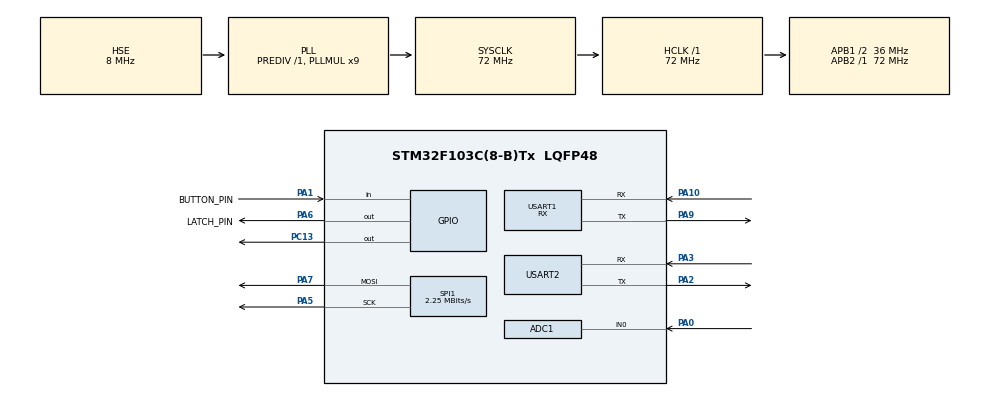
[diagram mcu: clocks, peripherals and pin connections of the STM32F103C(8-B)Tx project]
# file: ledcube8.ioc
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ADC1.Channel-2\#ChannelRegularConversion=ADC_CHANNEL_0
ADC1.NbrOfConversionFlag=1
ADC1.Rank-2\#ChannelRegularConversion=1
ADC1.SamplingTime-2\#ChannelRegularConversion=ADC_SAMPLETIME_1CYCLE_5
ADC1.master=1
Mcu.Family=STM32F1
Mcu.Name=STM32F103C(8-B)Tx
Mcu.Package=LQFP48
NVIC.PriorityGroup=NVIC_PRIORITYGROUP_4
NVIC.TIM2_IRQn=true\:2\:0\:true\:false\:true\:true\:true\:true
NVIC.USART1_IRQn=true\:0\:0\:false\:false\:true\:true\:true\:true
NVIC.USART2_IRQn=true\:0\:0\:false\:false\:true\:true\:true\:true
PA0-WKUP.Signal=ADCx_IN0
PA1.GPIO_Label=BUTTON_PIN
PA1.GPIO_PuPd=GPIO_PULLUP
PA1.Signal=GPIO_Input
PA10.Mode=Asynchronous
PA10.Signal=USART1_RX
PA13.Mode=Serial_Wire
PA13.Signal=SYS_JTMS-SWDIO
PA14.Mode=Serial_Wire
PA14.Signal=SYS_JTCK-SWCLK
PA2.Mode=Asynchronous
PA2.Signal=USART2_TX
PA3.Mode=Asynchronous
PA3.Signal=USART2_RX
PA5.Mode=TX_Only_Simplex_Unidirect_Master
PA5.Signal=SPI1_SCK
PA6.GPIO_Label=LATCH_PIN
PA6.Signal=GPIO_Output
PA7.Mode=TX_Only_Simplex_Unidirect_Master
PA7.Signal=SPI1_MOSI
PA9.Mode=Asynchronous
PA9.Signal=USART1_TX
PC13-TAMPER-RTC.Signal=GPIO_Output
PD0-OSC_IN.Mode=HSE-External-Oscillator
PD0-OSC_IN.Signal=RCC_OSC_IN
PD1-OSC_OUT.Mode=HSE-External-Oscillator
PD1-OSC_OUT.Signal=RCC_OSC_OUT
ProjectManager.HeapSize=0x200
ProjectManager.StackSize=0x400
ProjectManager.TargetToolchain=STM32CubeIDE
RCC.ADCPresc=RCC_ADCPCLK2_DIV6
RCC.AHBFreq_Value=72000000
RCC.APB1CLKDivider=RCC_HCLK_DIV2
RCC.APB1Freq_Value=36000000
RCC.APB1TimFreq_Value=72000000
RCC.APB2Freq_Value=72000000
RCC.APB2TimFreq_Value=72000000
RCC.HCLKFreq_Value=72000000
RCC.PLLMUL=RCC_PLL_MUL9
RCC.PLLSourceVirtual=RCC_PLLSOURCE_HSE
RCC.SYSCLKFreq_VALUE=72000000
RCC.SYSCLKSource=RCC_SYSCLKSOURCE_PLLCLK
RCC.USBFreq_Value=72000000
SH.ADCx_IN0.0=ADC1_IN0,IN0
SPI1.BaudRatePrescaler=SPI_BAUDRATEPRESCALER_32
SPI1.CalculateBaudRate=2.25 MBits/s
SPI1.Direction=SPI_DIRECTION_2LINES
SPI1.Mode=SPI_MODE_MASTER
SPI1.VirtualType=VM_MASTER
TIM2.AutoReloadPreload=TIM_AUTORELOAD_PRELOAD_ENABLE
TIM2.Period=199
TIM2.Prescaler=\ 35999
USART1.Mode=MODE_RX
USART1.VirtualMode=VM_ASYNC
USART2.VirtualMode=VM_ASYNC
VP_TIM2_VS_ClockSourceINT.Mode=Internal
board=custom

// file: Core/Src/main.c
/* USER CODE BEGIN Header */
/**
  ******************************************************************************
  * @file           : main.c
  * @brief          : Main program body
  ******************************************************************************
  * @attention
  *
  * Copyright (c) 2022 STMicroelectronics.
  * All rights reserved.
  *
  * This software is licensed under terms that can be found in the LICENSE file
  * in the root directory of this software component.
  * If no LICENSE file comes with this software, it is provided AS-IS.
  *
  ******************************************************************************
  */
/* USER CODE END Header */
#include "main.h"

/* USER CODE BEGIN Includes */
#include "led_cube_handle.h"
/* USER CODE END Includes */

ADC_HandleTypeDef hadc1;

SPI_HandleTypeDef hspi1;

TIM_HandleTypeDef htim2;

UART_HandleTypeDef huart1;
UART_HandleTypeDef huart2;

/* USER CODE BEGIN PV */
uint8_t rxData;
uint8_t txData;
Btn_Typedef button1;
/* USER CODE END PV */

void SystemClock_Config(void);
static void MX_GPIO_Init(void);
static void MX_SPI1_Init(void);
static void MX_USART1_UART_Init(void);
static void MX_USART2_UART_Init(void);
static void MX_ADC1_Init(void);
static void MX_TIM2_Init(void);

/* USER CODE BEGIN 0 */
void HAL_UART_RxCpltCallback(UART_HandleTypeDef *huart)
{
	if (huart2.Instance == huart ->Instance)
	{
		HAL_UART_Receive_IT(&huart2, &rxData, 1);
		currentEffect = rxData;
	}
}

//void HAL_TIM_PeriodElapsedCallback(TIM_HandleTypeDef *htim)
//{
//	 if(htim->Instance == htim2.Instance)
//	 {
//		 txData = currentEffect + 48;
//		 HAL_UART_Transmit(&huart2, &txData, 1, 100);
//	 }
//}
/* USER CODE END 0 */

int main(void)
{

  /* MCU Configuration--------------------------------------------------------*/

  /* Reset of all peripherals, Initializes the Flash interface and the Systick. */
  HAL_Init();

  /* USER CODE BEGIN Init */
  Btn_Init(&button1, GPIOA, GPIO_PIN_1);
  /* USER CODE END Init */

  /* Configure the system clock */
  SystemClock_Config();

  /* Initialize all configured peripherals */
  MX_GPIO_Init();
  MX_SPI1_Init();
  MX_USART1_UART_Init();
  MX_USART2_UART_Init();
  MX_ADC1_Init();
  MX_TIM2_Init();
  /* USER CODE BEGIN 2 */
  HAL_UART_Receive_IT(&huart2, &rxData, 1);
  HAL_TIM_Base_Start_IT(&htim2);
  /* USER CODE END 2 */

  /* Infinite loop */
  while (1)
  {

    /* USER CODE BEGIN 3 */
	  Btn_Handle(&button1);
	  Led_cube_Handle(currentEffect);
  }
  /* USER CODE END 3 */
}

void SystemClock_Config(void)
{
  RCC_OscInitTypeDef RCC_OscInitStruct = {0};
  RCC_ClkInitTypeDef RCC_ClkInitStruct = {0};
  RCC_PeriphCLKInitTypeDef PeriphClkInit = {0};

  /** Initializes the RCC Oscillators according to the specified parameters
  * in the RCC_OscInitTypeDef structure.
  */
  RCC_OscInitStruct.OscillatorType = RCC_OSCILLATORTYPE_HSE;
  RCC_OscInitStruct.HSEState = RCC_HSE_ON;
  RCC_OscInitStruct.HSEPredivValue = RCC_HSE_PREDIV_DIV1;
  RCC_OscInitStruct.HSIState = RCC_HSI_ON;
  RCC_OscInitStruct.PLL.PLLState = RCC_PLL_ON;
  RCC_OscInitStruct.PLL.PLLSource = RCC_PLLSOURCE_HSE;
  RCC_OscInitStruct.PLL.PLLMUL = RCC_PLL_MUL9;
  if (HAL_RCC_OscConfig(&RCC_OscInitStruct) != HAL_OK)
  {
    Error_Handler();
  }

  /** Initializes the CPU, AHB and APB buses clocks
  */
  RCC_ClkInitStruct.ClockType = RCC_CLOCKTYPE_HCLK|RCC_CLOCKTYPE_SYSCLK
                              |RCC_CLOCKTYPE_PCLK1|RCC_CLOCKTYPE_PCLK2;
  RCC_ClkInitStruct.SYSCLKSource = RCC_SYSCLKSOURCE_PLLCLK;
  RCC_ClkInitStruct.AHBCLKDivider = RCC_SYSCLK_DIV1;
  RCC_ClkInitStruct.APB1CLKDivider = RCC_HCLK_DIV2;
  RCC_ClkInitStruct.APB2CLKDivider = RCC_HCLK_DIV1;

  if (HAL_RCC_ClockConfig(&RCC_ClkInitStruct, FLASH_LATENCY_2) != HAL_OK)
  {
    Error_Handler();
  }
  PeriphClkInit.PeriphClockSelection = RCC_PERIPHCLK_ADC;
  PeriphClkInit.AdcClockSelection = RCC_ADCPCLK2_DIV6;
  if (HAL_RCCEx_PeriphCLKConfig(&PeriphClkInit) != HAL_OK)
  {
    Error_Handler();
  }
}

static void MX_ADC1_Init(void)
{

  ADC_ChannelConfTypeDef sConfig = {0};

  /** Common config
  */
  hadc1.Instance = ADC1;
  hadc1.Init.ScanConvMode = ADC_SCAN_DISABLE;
  hadc1.Init.ContinuousConvMode = DISABLE;
  hadc1.Init.DiscontinuousConvMode = DISABLE;
  hadc1.Init.ExternalTrigConv = ADC_SOFTWARE_START;
  hadc1.Init.DataAlign = ADC_DATAALIGN_RIGHT;
  hadc1.Init.NbrOfConversion = 1;
  if (HAL_ADC_Init(&hadc1) != HAL_OK)
  {
    Error_Handler();
  }

  /** Configure Regular Channel
  */
  sConfig.Channel = ADC_CHANNEL_0;
  sConfig.Rank = ADC_REGULAR_RANK_1;
  sConfig.SamplingTime = ADC_SAMPLETIME_1CYCLE_5;
  if (HAL_ADC_ConfigChannel(&hadc1, &sConfig) != HAL_OK)
  {
    Error_Handler();
  }

}

static void MX_SPI1_Init(void)
{

  /* SPI1 parameter configuration*/
  hspi1.Instance = SPI1;
  hspi1.Init.Mode = SPI_MODE_MASTER;
  hspi1.Init.Direction = SPI_DIRECTION_2LINES;
  hspi1.Init.DataSize = SPI_DATASIZE_8BIT;
  hspi1.Init.CLKPolarity = SPI_POLARITY_LOW;
  hspi1.Init.CLKPhase = SPI_PHASE_1EDGE;
  hspi1.Init.NSS = SPI_NSS_SOFT;
  hspi1.Init.BaudRatePrescaler = SPI_BAUDRATEPRESCALER_32;
  hspi1.Init.FirstBit = SPI_FIRSTBIT_MSB;
  hspi1.Init.TIMode = SPI_TIMODE_DISABLE;
  hspi1.Init.CRCCalculation = SPI_CRCCALCULATION_DISABLE;
  hspi1.Init.CRCPolynomial = 10;
  if (HAL_SPI_Init(&hspi1) != HAL_OK)
  {
    Error_Handler();
  }

}

static void MX_TIM2_Init(void)
{

  TIM_ClockConfigTypeDef sClockSourceConfig = {0};
  TIM_MasterConfigTypeDef sMasterConfig = {0};

  htim2.Instance = TIM2;
  htim2.Init.Prescaler = 35999;
  htim2.Init.CounterMode = TIM_COUNTERMODE_UP;
  htim2.Init.Period = 199;
  htim2.Init.ClockDivision = TIM_CLOCKDIVISION_DIV1;
  htim2.Init.AutoReloadPreload = TIM_AUTORELOAD_PRELOAD_ENABLE;
  if (HAL_TIM_Base_Init(&htim2) != HAL_OK)
  {
    Error_Handler();
  }
  sClockSourceConfig.ClockSource = TIM_CLOCKSOURCE_INTERNAL;
  if (HAL_TIM_ConfigClockSource(&htim2, &sClockSourceConfig) != HAL_OK)
  {
    Error_Handler();
  }
  sMasterConfig.MasterOutputTrigger = TIM_TRGO_RESET;
  sMasterConfig.MasterSlaveMode = TIM_MASTERSLAVEMODE_DISABLE;
  if (HAL_TIMEx_MasterConfigSynchronization(&htim2, &sMasterConfig) != HAL_OK)
  {
    Error_Handler();
  }

}

static void MX_USART1_UART_Init(void)
{

  huart1.Instance = USART1;
  huart1.Init.BaudRate = 115200;
  huart1.Init.WordLength = UART_WORDLENGTH_8B;
  huart1.Init.StopBits = UART_STOPBITS_1;
  huart1.Init.Parity = UART_PARITY_NONE;
  huart1.Init.Mode = UART_MODE_RX;
  huart1.Init.HwFlowCtl = UART_HWCONTROL_NONE;
  huart1.Init.OverSampling = UART_OVERSAMPLING_16;
  if (HAL_UART_Init(&huart1) != HAL_OK)
  {
    Error_Handler();
  }

}

static void MX_USART2_UART_Init(void)
{

  huart2.Instance = USART2;
  huart2.Init.BaudRate = 115200;
  huart2.Init.WordLength = UART_WORDLENGTH_8B;
  huart2.Init.StopBits = UART_STOPBITS_1;
  huart2.Init.Parity = UART_PARITY_NONE;
  huart2.Init.Mode = UART_MODE_TX_RX;
  huart2.Init.HwFlowCtl = UART_HWCONTROL_NONE;
  huart2.Init.OverSampling = UART_OVERSAMPLING_16;
  if (HAL_UART_Init(&huart2) != HAL_OK)
  {
    Error_Handler();
  }

}

static void MX_GPIO_Init(void)
{
  GPIO_InitTypeDef GPIO_InitStruct = {0};

  /* GPIO Ports Clock Enable */
  __HAL_RCC_GPIOC_CLK_ENABLE();
  __HAL_RCC_GPIOD_CLK_ENABLE();
  __HAL_RCC_GPIOA_CLK_ENABLE();

  /*Configure GPIO pin Output Level */
  HAL_GPIO_WritePin(GPIOC, GPIO_PIN_13, GPIO_PIN_RESET);

  /*Configure GPIO pin Output Level */
  HAL_GPIO_WritePin(LATCH_PIN_GPIO_Port, LATCH_PIN_Pin, GPIO_PIN_RESET);

  /*Configure GPIO pin : PC13 */
  GPIO_InitStruct.Pin = GPIO_PIN_13;
  GPIO_InitStruct.Mode = GPIO_MODE_OUTPUT_PP;
  GPIO_InitStruct.Pull = GPIO_NOPULL;
  GPIO_InitStruct.Speed = GPIO_SPEED_FREQ_LOW;
  HAL_GPIO_Init(GPIOC, &GPIO_InitStruct);

  /*Configure GPIO pin : BUTTON_PIN_Pin */
  GPIO_InitStruct.Pin = BUTTON_PIN_Pin;
  GPIO_InitStruct.Mode = GPIO_MODE_INPUT;
  GPIO_InitStruct.Pull = GPIO_PULLUP;
  HAL_GPIO_Init(BUTTON_PIN_GPIO_Port, &GPIO_InitStruct);

  /*Configure GPIO pin : LATCH_PIN_Pin */
  GPIO_InitStruct.Pin = LATCH_PIN_Pin;
  GPIO_InitStruct.Mode = GPIO_MODE_OUTPUT_PP;
  GPIO_InitStruct.Pull = GPIO_NOPULL;
  GPIO_InitStruct.Speed = GPIO_SPEED_FREQ_LOW;
  HAL_GPIO_Init(LATCH_PIN_GPIO_Port, &GPIO_InitStruct);

}

void Error_Handler(void)
{
  __disable_irq();
  while (1)
  {
  }
}
